AUTOSAR XML (schema 4.0)
package /S03FIX/If
  sender receiver interface CanBridge
    data val
  sender receiver interface CanFrame
    data val
package /S03FIX/Swc
  application sw component type InfotainmentClient
    provide port icToGwOut: provided-interface=CanBridge
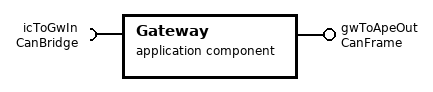
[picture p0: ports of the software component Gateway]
  application sw component type Gateway
    provide port gwToApeOut: provided-interface=CanFrame
    require port icToGwIn: required-interface=CanBridge
  application sw component type AutopilotEcu
    require port gwToApeIn: required-interface=CanFrame
  composition sw component type Root
    component ic: type=InfotainmentClient
    component gw: type=Gateway
    component ape: type=AutopilotEcu
    connect ic.icToGwOut -> gw.icToGwIn
    connect gw.gwToApeOut -> ape.gwToApeIn
package /S03FIX/Comm
  pdu icToGwIPdu
    signal icToGwISig: system signal icToGwSSig
  secured i pdu icToGwSecuredIPdu: auth-info-tx-length=32, freshness-value-id=1, freshness-value-length=8, payload=icToGwIPdu
  pdu gwToApeIPdu
    signal gwToApeISig: system signal gwToApeSSig
  secured i pdu gwToApeSecuredIPdu: auth-info-tx-length=32, freshness-value-id=1, freshness-value-length=8, payload=gwToApeIPdu
package /S03FIX/Topology
  ecu instance ApeEcu
  ecu instance GatewayEcu
  ecu instance IcEcu
  system Veh
    root-software-compositions:
      root sw composition prototype Root: software-composition=Root
    system mapping Map
      data-mappings:
        data-element=Root.icToGwOut.val, system-signal=icToGwSSig
        data-element=Root.gwToApeOut.val, system-signal=gwToApeSSig
      sw-mappings:
        swc to ecu mapping ToApeEcu: component=ape, ecu-instance=ApeEcu
        swc to ecu mapping ToGatewayEcu: component=gw, ecu-instance=GatewayEcu
        swc to ecu mapping ToIcEcu: component=ic, ecu-instance=IcEcu
